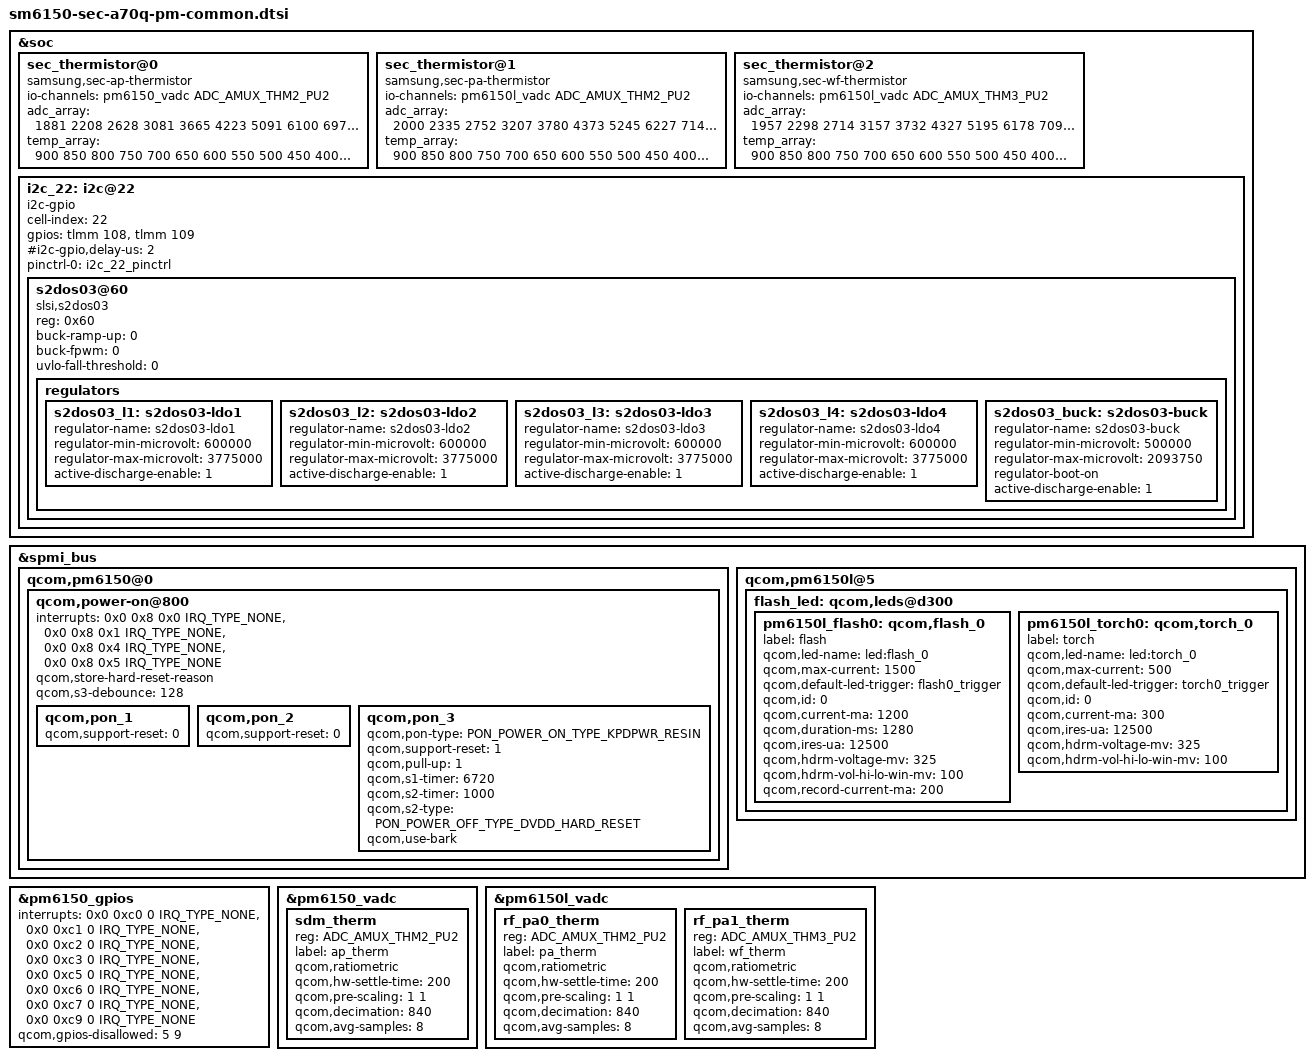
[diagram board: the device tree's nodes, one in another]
/* Copyright (c) 2018, The Linux Foundation. All rights reserved.
 *
 * This program is free software; you can redistribute it and/or modify
 * it under the terms of the GNU General Public License version 2 and
 * only version 2 as published by the Free Software Foundation.
 *
 * This program is distributed in the hope that it will be useful,
 * but WITHOUT ANY WARRANTY; without even the implied warranty of
 * MERCHANTABILITY or FITNESS FOR A PARTICULAR PURPOSE.  See the
 * GNU General Public License for more details.
 */
#include <dt-bindings/input/qcom,qpnp-power-on.h>

&soc {
	/* AP Thermistor table */
	sec_thermistor@0 {
		compatible = "samsung,sec-ap-thermistor";
		status = "okay";
		io-channels = <&pm6150_vadc ADC_AMUX_THM2_PU2>;
		io-channel-names = "ap_therm";
		adc_array = <1881 2208 2628 3081 3665 4223 5091 6100 6971 8092 9435
					 10870 12425 14088 15876 17588 19413 20626
					 22139
					 23387 24546 25490 26016>;
		temp_array = <900 850 800 750 700 650 600 550 500 450 400
					 350 300 250 200 150 100 50
					 0
					 (-50) (-100) (-150) (-200)>;
	};

	/* PA Thermistor table */
	sec_thermistor@1 {
		compatible = "samsung,sec-pa-thermistor";
		status = "okay";
		io-channels = <&pm6150l_vadc ADC_AMUX_THM2_PU2>;
		io-channel-names = "pa_therm";
		adc_array = <2000 2335 2752 3207 3780 4373 5245 6227 7143 8277 9627
					 11047 12666 14287 16130 17811 19629 20891
					 22382
					 23605 24725 25638 26189>;
		temp_array = <900 850 800 750 700 650 600 550 500 450 400
					 350 300 250 200 150 100 50
					 0
					 (-50) (-100) (-150) (-200)>;
	};

	/* WiFi Thermistor table */
	sec_thermistor@2 {
		compatible = "samsung,sec-wf-thermistor";
		status = "okay";
		io-channels = <&pm6150l_vadc ADC_AMUX_THM3_PU2>;
		io-channel-names = "wf_therm";
		adc_array = <1957 2298 2714 3157 3732 4327 5195 6178 7091 8215 9553
					 11000 12575 14194 16036 17727 19530 20828
					 22308
					 23540 24672 25597 26163>;
		temp_array = <900 850 800 750 700 650 600 550 500 450 400
					 350 300 250 200 150 100 50
					 0
					 (-50) (-100) (-150) (-200)>;
	};

 	i2c_22: i2c@22 {
		/* S2DOS03 Display PMIC */
		status = "ok";

		cell-index = <22>;
		compatible = "i2c-gpio";
		gpios = <&tlmm 108 0	/* OCTA_PMIC_SDA_1P8 */
			 &tlmm 109 0	/* OCTA_PMIC_SCL_1P8 */
		>;
		#i2c-gpio,delay-us = <2>;
		#address-cells = <1>;
		#size-cells = <0>;

		pinctrl-names = "default";
		pinctrl-0 = <&i2c_22_pinctrl>;

		s2dos03@60 {
			compatible = "slsi,s2dos03";
			reg = <0x60>;

			buck-ramp-up = <0>;		/* 6.25mV/us */
			buck-fpwm = <0>;		/* Disable */

			uvlo-fall-threshold = <0>;	/* 2.30V */

			regulators {
				s2dos03_l1: s2dos03-ldo1 {
					regulator-name = "s2dos03-ldo1";
					regulator-min-microvolt = <600000>;
					regulator-max-microvolt = <3775000>;
					active-discharge-enable = <1>;
				};

				s2dos03_l2: s2dos03-ldo2 {
					regulator-name = "s2dos03-ldo2";
					regulator-min-microvolt = <600000>;
					regulator-max-microvolt = <3775000>;
					active-discharge-enable = <1>;
				};

				s2dos03_l3: s2dos03-ldo3 {
					regulator-name = "s2dos03-ldo3";
					regulator-min-microvolt = <600000>;
					regulator-max-microvolt = <3775000>;
					active-discharge-enable = <1>;
				};

				s2dos03_l4: s2dos03-ldo4 {
					regulator-name = "s2dos03-ldo4";
					regulator-min-microvolt = <600000>;
					regulator-max-microvolt = <3775000>;
					active-discharge-enable = <1>;
				};

				s2dos03_buck: s2dos03-buck {
					regulator-name = "s2dos03-buck";
					regulator-min-microvolt = <500000>;
					regulator-max-microvolt = <2093750>;
					regulator-boot-on; /* from DREAMQ */
					active-discharge-enable = <1>;
				};
			};
		};
	};
};

&spmi_bus {
	qcom,pm6150@0{
		qcom,power-on@800 {
			interrupts = <0x0 0x8 0x0 IRQ_TYPE_NONE>,
					<0x0 0x8 0x1 IRQ_TYPE_NONE>,
					<0x0 0x8 0x4 IRQ_TYPE_NONE>,
					<0x0 0x8 0x5 IRQ_TYPE_NONE>;
			interrupt-names = "kpdpwr", "resin",
					"resin-bark", "kpdpwr-resin-bark";
			qcom,store-hard-reset-reason;
			qcom,s3-debounce = <128>;

			qcom,pon_1 {
				qcom,support-reset = <0>;
			};

			qcom,pon_2 {
				qcom,support-reset = <0>;
			};

			qcom,pon_3 {
				qcom,pon-type = <PON_POWER_ON_TYPE_KPDPWR_RESIN>;
				qcom,support-reset = <1>;
				qcom,pull-up = <1>;
				qcom,s1-timer = <6720>;
				qcom,s2-timer = <1000>;
				qcom,s2-type = <PON_POWER_OFF_TYPE_DVDD_HARD_RESET>;
				qcom,use-bark;
			};
		};
	};

	qcom,pm6150l@5 {
		flash_led: qcom,leds@d300 {
			pm6150l_flash0: qcom,flash_0 {
				label = "flash";
				qcom,led-name = "led:flash_0";
				qcom,max-current = <1500>;
				qcom,default-led-trigger = "flash0_trigger";
				qcom,id = <0>;
				qcom,current-ma = <1200>;
				qcom,duration-ms = <1280>;
				qcom,ires-ua = <12500>;
				qcom,hdrm-voltage-mv = <325>;
				qcom,hdrm-vol-hi-lo-win-mv = <100>;
				qcom,record-current-ma = <200>;
			};
			pm6150l_torch0: qcom,torch_0 {
				label = "torch";
				qcom,led-name = "led:torch_0";
				qcom,max-current = <500>;
				qcom,default-led-trigger = "torch0_trigger";
				qcom,id = <0>;
				qcom,current-ma = <300>;
				qcom,ires-ua = <12500>;
				qcom,hdrm-voltage-mv = <325>;
				qcom,hdrm-vol-hi-lo-win-mv = <100>;
			};
		};			
	};
};
&pm6150_gpios {
    interrupts = <0x0 0xc0 0 IRQ_TYPE_NONE>,
            <0x0 0xc1 0 IRQ_TYPE_NONE>,
            <0x0 0xc2 0 IRQ_TYPE_NONE>,
            <0x0 0xc3 0 IRQ_TYPE_NONE>,
			<0x0 0xc5 0 IRQ_TYPE_NONE>,
            <0x0 0xc6 0 IRQ_TYPE_NONE>,
            <0x0 0xc7 0 IRQ_TYPE_NONE>,
            <0x0 0xc9 0 IRQ_TYPE_NONE>;
    interrupt-names = "pm6150_gpio1", "pm6150_gpio2",
            "pm6150_gpio3", "pm6150_gpio4", "pm6150_gpio6",
            "pm6150_gpio7", "pm6150_gpio8",
            "pm6150_gpio10";
    qcom,gpios-disallowed = <5 9>;
};

&pm6150_vadc {
	sdm_therm {
		reg = <ADC_AMUX_THM2_PU2>;
		label = "ap_therm";
		qcom,ratiometric;
		qcom,hw-settle-time = <200>;
		qcom,pre-scaling = <1 1>;
		qcom,decimation = <840>;
		qcom,avg-samples = <8>;
	};
};

&pm6150l_vadc {
	rf_pa0_therm {
		reg = <ADC_AMUX_THM2_PU2>;
		label = "pa_therm";
		qcom,ratiometric;
		qcom,hw-settle-time = <200>;
		qcom,pre-scaling = <1 1>;
		qcom,decimation = <840>;
		qcom,avg-samples = <8>;
	};

	rf_pa1_therm {
		reg = <ADC_AMUX_THM3_PU2>;
		label = "wf_therm";
		qcom,ratiometric;
		qcom,hw-settle-time = <200>;
		qcom,pre-scaling = <1 1>;
		qcom,decimation = <840>;
		qcom,avg-samples = <8>;
	};
};
